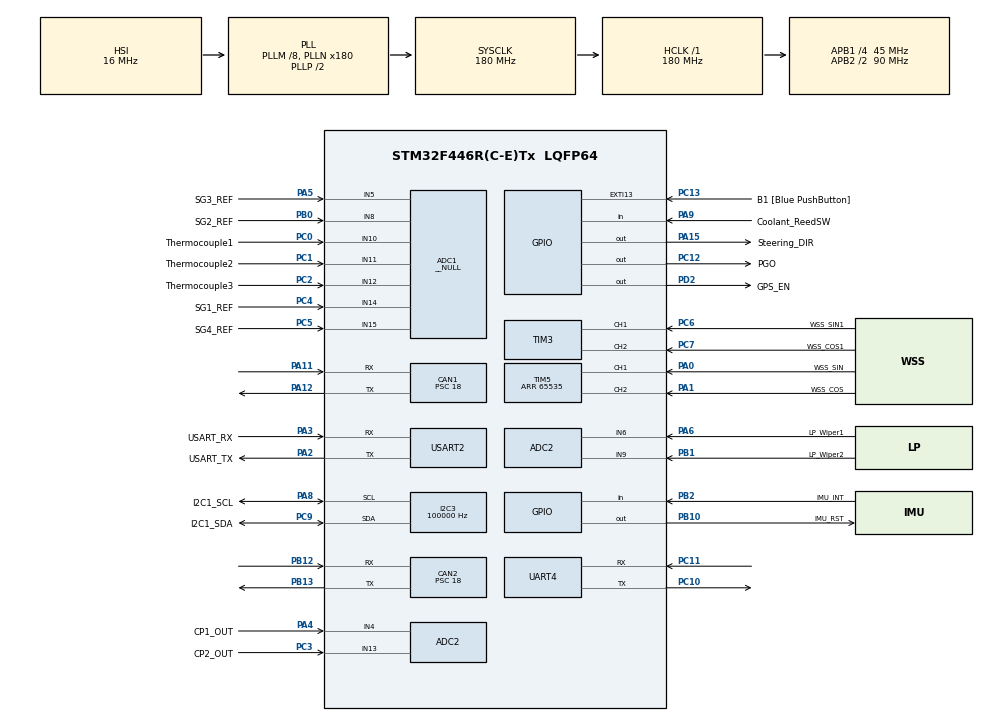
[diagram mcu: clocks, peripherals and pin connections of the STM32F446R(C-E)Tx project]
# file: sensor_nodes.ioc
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ADC1.Channel-0\#ChannelRegularConversion=ADC_CHANNEL_14
ADC1.Channel-1\#ChannelRegularConversion=ADC_CHANNEL_8
ADC1.Channel-2\#ChannelRegularConversion=ADC_CHANNEL_5
ADC1.Channel-3\#ChannelRegularConversion=ADC_CHANNEL_15
ADC1.Channel-4\#ChannelRegularConversion=ADC_CHANNEL_10
ADC1.Channel-5\#ChannelRegularConversion=ADC_CHANNEL_11
ADC1.Channel-6\#ChannelRegularConversion=ADC_CHANNEL_12
ADC1.ContinuousConvMode=DISABLE
ADC1.DMAContinuousRequests=DISABLE
ADC1.EOCSelection=ADC_EOC_SEQ_CONV
ADC1.Mode=__NULL
ADC1.NbrOfConversion=7
ADC1.NbrOfConversionFlag=1
ADC1.Rank-0\#ChannelRegularConversion=1
ADC1.Rank-1\#ChannelRegularConversion=2
ADC1.Rank-2\#ChannelRegularConversion=3
ADC1.Rank-3\#ChannelRegularConversion=4
ADC1.Rank-4\#ChannelRegularConversion=5
ADC1.Rank-5\#ChannelRegularConversion=6
ADC1.Rank-6\#ChannelRegularConversion=7
ADC1.SamplingTime-0\#ChannelRegularConversion=ADC_SAMPLETIME_3CYCLES
ADC1.SamplingTime-1\#ChannelRegularConversion=ADC_SAMPLETIME_3CYCLES
ADC1.SamplingTime-2\#ChannelRegularConversion=ADC_SAMPLETIME_3CYCLES
ADC1.SamplingTime-3\#ChannelRegularConversion=ADC_SAMPLETIME_3CYCLES
ADC1.SamplingTime-4\#ChannelRegularConversion=ADC_SAMPLETIME_3CYCLES
ADC1.SamplingTime-5\#ChannelRegularConversion=ADC_SAMPLETIME_3CYCLES
ADC1.SamplingTime-6\#ChannelRegularConversion=ADC_SAMPLETIME_3CYCLES
ADC1.master=1
ADC2.Channel-0\#ChannelRegularConversion=ADC_CHANNEL_6
ADC2.Channel-1\#ChannelRegularConversion=ADC_CHANNEL_9
ADC2.Channel-2\#ChannelRegularConversion=ADC_CHANNEL_4
ADC2.Channel-4\#ChannelRegularConversion=ADC_CHANNEL_13
ADC2.ContinuousConvMode=DISABLE
ADC2.DMAContinuousRequests=DISABLE
ADC2.DiscontinuousConvMode=DISABLE
ADC2.EOCSelection=ADC_EOC_SINGLE_CONV
ADC2.InjNumberOfConversion=0
ADC2.NbrOfConversion=4
ADC2.NbrOfConversionFlag=1
ADC2.Rank-0\#ChannelRegularConversion=1
ADC2.Rank-1\#ChannelRegularConversion=2
ADC2.Rank-2\#ChannelRegularConversion=3
ADC2.Rank-4\#ChannelRegularConversion=4
ADC2.SamplingTime-0\#ChannelRegularConversion=ADC_SAMPLETIME_112CYCLES
ADC2.SamplingTime-1\#ChannelRegularConversion=ADC_SAMPLETIME_112CYCLES
ADC2.SamplingTime-2\#ChannelRegularConversion=ADC_SAMPLETIME_112CYCLES
ADC2.SamplingTime-4\#ChannelRegularConversion=ADC_SAMPLETIME_112CYCLES
CAN1.BS1=CAN_BS1_3TQ
CAN1.BS2=CAN_BS2_1TQ
CAN1.CalculateBaudRate=500000
CAN1.CalculateTimeBit=2000
CAN1.CalculateTimeQuantum=400.0
CAN1.Prescaler=18
CAN2.BS1=CAN_BS1_3TQ
CAN2.BS2=CAN_BS2_1TQ
CAN2.CalculateBaudRate=500000
CAN2.CalculateTimeBit=2000
CAN2.CalculateTimeQuantum=400.0
CAN2.Prescaler=18
I2C3.ClockSpeed=100000
I2C3.DualAddressMode=I2C_DUALADDRESS_DISABLE
I2C3.I2C_Mode=I2C_Standard
I2C3.NoStretchMode=I2C_NOSTRETCH_DISABLE
I2C3.OwnAddress=0x4A
Mcu.Family=STM32F4
Mcu.Name=STM32F446R(C-E)Tx
Mcu.Package=LQFP64
NVIC.ADC_IRQn=true\:0\:0\:false\:false\:true\:true\:true\:true
NVIC.CAN1_RX0_IRQn=true\:0\:0\:false\:false\:true\:true\:true\:true
NVIC.CAN1_RX1_IRQn=true\:0\:0\:false\:false\:true\:true\:true\:true
NVIC.CAN2_RX0_IRQn=true\:0\:0\:false\:false\:true\:true\:true\:true
NVIC.CAN2_RX1_IRQn=true\:0\:0\:false\:false\:true\:true\:true\:true
NVIC.PriorityGroup=NVIC_PRIORITYGROUP_0
NVIC.TIM6_DAC_IRQn=true\:0\:0\:false\:false\:true\:true\:true\:true
PA0-WKUP.GPIO_Label=WSS_SIN
PA0-WKUP.Signal=S_TIM5_CH1
PA1.GPIO_Label=WSS_COS
PA1.Signal=S_TIM5_CH2
PA11.Mode=CAN_Activate
PA11.Signal=CAN1_RX
PA12.Mode=CAN_Activate
PA12.Signal=CAN1_TX
PA13.GPIO_Label=TMS
PA13.Mode=Serial_Wire
PA13.Signal=SYS_JTMS-SWDIO
PA14.GPIO_Label=TCK
PA14.Mode=Serial_Wire
PA14.Signal=SYS_JTCK-SWCLK
PA15.GPIO_Label=Steering_DIR
PA15.Signal=GPIO_Output
PA2.GPIO_Label=USART_TX
PA2.Mode=Asynchronous
PA2.Signal=USART2_TX
PA3.GPIO_Label=USART_RX
PA3.Mode=Asynchronous
PA3.Signal=USART2_RX
PA4.GPIO_Label=CP1_OUT
PA4.Signal=ADCx_IN4
PA5.GPIO_Label=SG3_REF
PA5.Signal=ADCx_IN5
PA6.GPIO_Label=LP_Wiper1
PA6.Signal=ADCx_IN6
PA8.GPIO_Label=I2C1_SCL
PA8.Mode=I2C
PA8.Signal=I2C3_SCL
PA9.GPIO_Label=Coolant_ReedSW
PA9.Signal=GPIO_Input
PB0.GPIO_Label=SG2_REF
PB0.Signal=ADCx_IN8
PB1.GPIO_Label=LP_Wiper2
PB1.Signal=ADCx_IN9
PB10.GPIO_Label=IMU_RST
PB10.Signal=GPIO_Output
PB12.Mode=CAN_Activate
PB12.Signal=CAN2_RX
PB13.Mode=CAN_Activate
PB13.Signal=CAN2_TX
PB2.GPIO_Label=IMU_INT
PB2.Signal=GPIO_Input
PC0.GPIO_Label=Thermocouple1
PC0.Signal=ADCx_IN10
PC1.GPIO_Label=Thermocouple2
PC1.Signal=ADCx_IN11
PC10.Mode=Asynchronous
PC10.Signal=UART4_TX
PC11.Mode=Asynchronous
PC11.Signal=UART4_RX
PC12.GPIO_Label=PGO
PC12.Signal=GPIO_Output
PC13.GPIO_Label=B1 [Blue PushButton]
PC13.GPIO_ModeDefaultEXTI=GPIO_MODE_IT_FALLING
PC13.Signal=GPXTI13
PC14-OSC32_IN.Mode=LSE-External-Oscillator
PC14-OSC32_IN.Signal=RCC_OSC32_IN
PC15-OSC32_OUT.Mode=LSE-External-Oscillator
PC15-OSC32_OUT.Signal=RCC_OSC32_OUT
PC2.GPIO_Label=Thermocouple3
PC2.Signal=ADCx_IN12
PC3.GPIO_Label=CP2_OUT
PC3.Signal=ADCx_IN13
PC4.GPIO_Label=SG1_REF
PC4.Signal=ADCx_IN14
PC5.GPIO_Label=SG4_REF
PC5.Signal=ADCx_IN15
PC6.GPIO_Label=WSS_SIN1
PC6.Signal=S_TIM3_CH1
PC7.GPIO_Label=WSS_COS1
PC7.Signal=S_TIM3_CH2
PC9.GPIO_Label=I2C1_SDA
PC9.Mode=I2C
PC9.Signal=I2C3_SDA
PD2.GPIO_Label=GPS_EN
PD2.Signal=GPIO_Output
PH0-OSC_IN.Mode=HSE-External-Oscillator
PH0-OSC_IN.Signal=RCC_OSC_IN
PH1-OSC_OUT.Mode=HSE-External-Oscillator
PH1-OSC_OUT.Signal=RCC_OSC_OUT
ProjectManager.HeapSize=0x200
ProjectManager.StackSize=0x400
ProjectManager.TargetToolchain=STM32CubeIDE
RCC.48MHZClocksFreq_Value=84000000
RCC.AHBFreq_Value=180000000
RCC.APB1CLKDivider=RCC_HCLK_DIV4
RCC.APB1Freq_Value=45000000
RCC.APB1TimFreq_Value=90000000
RCC.APB2CLKDivider=RCC_HCLK_DIV2
RCC.APB2Freq_Value=90000000
RCC.APB2TimFreq_Value=180000000
RCC.CortexFreq_Value=180000000
RCC.FLatency-AdvancedSettings=FLASH_LATENCY_5
RCC.HCLKFreq_Value=180000000
RCC.HSE_VALUE=8000000
RCC.HSI_VALUE=16000000
RCC.PLLM=8
RCC.PLLN=180
RCC.SYSCLKFreq_VALUE=180000000
RCC.SYSCLKSource=RCC_SYSCLKSOURCE_PLLCLK
RCC.USBFreq_Value=180000000
RCC.VCOOutputFreq_Value=360000000
SH.ADCx_IN10.0=ADC1_IN10,IN10
SH.ADCx_IN11.0=ADC1_IN11,IN11
SH.ADCx_IN12.0=ADC1_IN12,IN12
SH.ADCx_IN13.0=ADC2_IN13,IN13
SH.ADCx_IN14.0=ADC1_IN14,IN14
SH.ADCx_IN15.0=ADC1_IN15,IN15
SH.ADCx_IN4.0=ADC2_IN4,IN4
SH.ADCx_IN5.0=ADC1_IN5,IN5
SH.ADCx_IN6.0=ADC2_IN6,IN6
SH.ADCx_IN8.0=ADC1_IN8,IN8
SH.ADCx_IN9.0=ADC2_IN9,IN9
SH.S_TIM3_CH1.0=TIM3_CH1,Encoder_Interface
SH.S_TIM3_CH2.0=TIM3_CH2,Encoder_Interface
SH.S_TIM5_CH1.0=TIM5_CH1,Encoder_Interface
SH.S_TIM5_CH2.0=TIM5_CH2,Encoder_Interface
TIM3.AutoReloadPreload=TIM_AUTORELOAD_PRELOAD_ENABLE
TIM3.EncoderMode=TIM_ENCODERMODE_TI12
TIM5.AutoReloadPreload=TIM_AUTORELOAD_PRELOAD_ENABLE
TIM5.EncoderMode=TIM_ENCODERMODE_TI12
TIM5.Period=65535
TIM6.AutoReloadPreload=TIM_AUTORELOAD_PRELOAD_ENABLE
TIM6.Period=10000-1
TIM6.Prescaler=4500-1
UART4.VirtualMode=Asynchronous
USART2.VirtualMode=VM_ASYNC
VP_TIM6_VS_ClockSourceINT.Mode=Enable_Timer
board=NUCLEO-F446RE

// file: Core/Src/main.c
/* USER CODE BEGIN Header */
/**
  ******************************************************************************
  * @file           : main.c
  * @brief          : Main program body
  ******************************************************************************
  * @attention
  *
  * Copyright (c) 2024 STMicroelectronics.
  * All rights reserved.
  *
  * This software is licensed under terms that can be found in the LICENSE file
  * in the root directory of this software component.
  * If no LICENSE file comes with this software, it is provided AS-IS.
  *
  ******************************************************************************
  */
/* USER CODE END Header */
#include "main.h"

/* USER CODE BEGIN Includes */
#include "FEB_Main.h"
/* USER CODE END Includes */

ADC_HandleTypeDef hadc1;
ADC_HandleTypeDef hadc2;

CAN_HandleTypeDef hcan1;
CAN_HandleTypeDef hcan2;

I2C_HandleTypeDef hi2c3;

TIM_HandleTypeDef htim3;
TIM_HandleTypeDef htim5;
TIM_HandleTypeDef htim6;

UART_HandleTypeDef huart4;
UART_HandleTypeDef huart2;

void SystemClock_Config(void);
static void MX_GPIO_Init(void);
static void MX_USART2_UART_Init(void);
static void MX_I2C3_Init(void);
static void MX_TIM6_Init(void);
static void MX_CAN1_Init(void);
static void MX_CAN2_Init(void);
static void MX_ADC1_Init(void);
static void MX_ADC2_Init(void);
static void MX_TIM3_Init(void);
static void MX_TIM5_Init(void);
static void MX_UART4_Init(void);

/* USER CODE BEGIN 0 */
#ifdef __GNUC__
#define PUTCHAR_PROTOTYPE int __io_putchar(int ch)
#else
#define PUTCHAR_PROTOTYPE int fputc(int ch, FILE *f)
#endif
PUTCHAR_PROTOTYPE {
  HAL_UART_Transmit(&huart2, (uint8_t *)&ch, 1, HAL_MAX_DELAY);
  return ch;
}
/* USER CODE END 0 */

int main(void)
{

  /* MCU Configuration--------------------------------------------------------*/

  /* Reset of all peripherals, Initializes the Flash interface and the Systick. */
  HAL_Init();

  /* Configure the system clock */
  SystemClock_Config();

  /* Initialize all configured peripherals */
  MX_GPIO_Init();
  MX_USART2_UART_Init();
  MX_I2C3_Init();
  MX_TIM6_Init();
  MX_CAN1_Init();
  MX_CAN2_Init();
  MX_ADC1_Init();
  MX_ADC2_Init();
  MX_TIM3_Init();
  MX_TIM5_Init();
  MX_UART4_Init();
  /* USER CODE BEGIN 2 */
  FEB_Main_Setup();
  /* USER CODE END 2 */

  /* Infinite loop */
  /* USER CODE BEGIN WHILE */
  while (1)
  {
	  FEB_Main_While();
    /* USER CODE END WHILE */

  }
}

void SystemClock_Config(void)
{
  RCC_OscInitTypeDef RCC_OscInitStruct = {0};
  RCC_ClkInitTypeDef RCC_ClkInitStruct = {0};

  /** Configure the main internal regulator output voltage
  */
  __HAL_RCC_PWR_CLK_ENABLE();
  __HAL_PWR_VOLTAGESCALING_CONFIG(PWR_REGULATOR_VOLTAGE_SCALE1);

  /** Initializes the RCC Oscillators according to the specified parameters
  * in the RCC_OscInitTypeDef structure.
  */
  RCC_OscInitStruct.OscillatorType = RCC_OSCILLATORTYPE_HSI;
  RCC_OscInitStruct.HSIState = RCC_HSI_ON;
  RCC_OscInitStruct.HSICalibrationValue = RCC_HSICALIBRATION_DEFAULT;
  RCC_OscInitStruct.PLL.PLLState = RCC_PLL_ON;
  RCC_OscInitStruct.PLL.PLLSource = RCC_PLLSOURCE_HSI;
  RCC_OscInitStruct.PLL.PLLM = 8;
  RCC_OscInitStruct.PLL.PLLN = 180;
  RCC_OscInitStruct.PLL.PLLP = RCC_PLLP_DIV2;
  RCC_OscInitStruct.PLL.PLLQ = 2;
  RCC_OscInitStruct.PLL.PLLR = 2;
  if (HAL_RCC_OscConfig(&RCC_OscInitStruct) != HAL_OK)
  {
    Error_Handler();
  }

  /** Activate the Over-Drive mode
  */
  if (HAL_PWREx_EnableOverDrive() != HAL_OK)
  {
    Error_Handler();
  }

  /** Initializes the CPU, AHB and APB buses clocks
  */
  RCC_ClkInitStruct.ClockType = RCC_CLOCKTYPE_HCLK|RCC_CLOCKTYPE_SYSCLK
                              |RCC_CLOCKTYPE_PCLK1|RCC_CLOCKTYPE_PCLK2;
  RCC_ClkInitStruct.SYSCLKSource = RCC_SYSCLKSOURCE_PLLCLK;
  RCC_ClkInitStruct.AHBCLKDivider = RCC_SYSCLK_DIV1;
  RCC_ClkInitStruct.APB1CLKDivider = RCC_HCLK_DIV4;
  RCC_ClkInitStruct.APB2CLKDivider = RCC_HCLK_DIV2;

  if (HAL_RCC_ClockConfig(&RCC_ClkInitStruct, FLASH_LATENCY_5) != HAL_OK)
  {
    Error_Handler();
  }
}

static void MX_ADC1_Init(void)
{

  ADC_ChannelConfTypeDef sConfig = {0};

  /** Configure the global features of the ADC (Clock, Resolution, Data Alignment and number of conversion)
  */
  hadc1.Instance = ADC1;
  hadc1.Init.ClockPrescaler = ADC_CLOCK_SYNC_PCLK_DIV4;
  hadc1.Init.Resolution = ADC_RESOLUTION_12B;
  hadc1.Init.ScanConvMode = ENABLE;
  hadc1.Init.ContinuousConvMode = DISABLE;
  hadc1.Init.DiscontinuousConvMode = DISABLE;
  hadc1.Init.ExternalTrigConvEdge = ADC_EXTERNALTRIGCONVEDGE_NONE;
  hadc1.Init.ExternalTrigConv = ADC_SOFTWARE_START;
  hadc1.Init.DataAlign = ADC_DATAALIGN_RIGHT;
  hadc1.Init.NbrOfConversion = 7;
  hadc1.Init.DMAContinuousRequests = DISABLE;
  hadc1.Init.EOCSelection = ADC_EOC_SEQ_CONV;
  if (HAL_ADC_Init(&hadc1) != HAL_OK)
  {
    Error_Handler();
  }

  /** Configure for the selected ADC regular channel its corresponding rank in the sequencer and its sample time.
  */
  sConfig.Channel = ADC_CHANNEL_14;
  sConfig.Rank = 1;
  sConfig.SamplingTime = ADC_SAMPLETIME_3CYCLES;
  if (HAL_ADC_ConfigChannel(&hadc1, &sConfig) != HAL_OK)
  {
    Error_Handler();
  }

  /** Configure for the selected ADC regular channel its corresponding rank in the sequencer and its sample time.
  */
  sConfig.Channel = ADC_CHANNEL_8;
  sConfig.Rank = 2;
  if (HAL_ADC_ConfigChannel(&hadc1, &sConfig) != HAL_OK)
  {
    Error_Handler();
  }

  /** Configure for the selected ADC regular channel its corresponding rank in the sequencer and its sample time.
  */
  sConfig.Channel = ADC_CHANNEL_5;
  sConfig.Rank = 3;
  if (HAL_ADC_ConfigChannel(&hadc1, &sConfig) != HAL_OK)
  {
    Error_Handler();
  }

  /** Configure for the selected ADC regular channel its corresponding rank in the sequencer and its sample time.
  */
  sConfig.Channel = ADC_CHANNEL_15;
  sConfig.Rank = 4;
  if (HAL_ADC_ConfigChannel(&hadc1, &sConfig) != HAL_OK)
  {
    Error_Handler();
  }

  /** Configure for the selected ADC regular channel its corresponding rank in the sequencer and its sample time.
  */
  sConfig.Channel = ADC_CHANNEL_10;
  sConfig.Rank = 5;
  if (HAL_ADC_ConfigChannel(&hadc1, &sConfig) != HAL_OK)
  {
    Error_Handler();
  }

  /** Configure for the selected ADC regular channel its corresponding rank in the sequencer and its sample time.
  */
  sConfig.Channel = ADC_CHANNEL_11;
  sConfig.Rank = 6;
  if (HAL_ADC_ConfigChannel(&hadc1, &sConfig) != HAL_OK)
  {
    Error_Handler();
  }

  /** Configure for the selected ADC regular channel its corresponding rank in the sequencer and its sample time.
  */
  sConfig.Channel = ADC_CHANNEL_12;
  sConfig.Rank = 7;
  if (HAL_ADC_ConfigChannel(&hadc1, &sConfig) != HAL_OK)
  {
    Error_Handler();
  }

}

static void MX_ADC2_Init(void)
{

  ADC_ChannelConfTypeDef sConfig = {0};

  /** Configure the global features of the ADC (Clock, Resolution, Data Alignment and number of conversion)
  */
  hadc2.Instance = ADC2;
  hadc2.Init.ClockPrescaler = ADC_CLOCK_SYNC_PCLK_DIV4;
  hadc2.Init.Resolution = ADC_RESOLUTION_12B;
  hadc2.Init.ScanConvMode = ENABLE;
  hadc2.Init.ContinuousConvMode = DISABLE;
  hadc2.Init.DiscontinuousConvMode = DISABLE;
  hadc2.Init.ExternalTrigConvEdge = ADC_EXTERNALTRIGCONVEDGE_NONE;
  hadc2.Init.ExternalTrigConv = ADC_SOFTWARE_START;
  hadc2.Init.DataAlign = ADC_DATAALIGN_RIGHT;
  hadc2.Init.NbrOfConversion = 4;
  hadc2.Init.DMAContinuousRequests = DISABLE;
  hadc2.Init.EOCSelection = ADC_EOC_SINGLE_CONV;
  if (HAL_ADC_Init(&hadc2) != HAL_OK)
  {
    Error_Handler();
  }

  /** Configure for the selected ADC regular channel its corresponding rank in the sequencer and its sample time.
  */
  sConfig.Channel = ADC_CHANNEL_6;
  sConfig.Rank = 1;
  sConfig.SamplingTime = ADC_SAMPLETIME_112CYCLES;
  if (HAL_ADC_ConfigChannel(&hadc2, &sConfig) != HAL_OK)
  {
    Error_Handler();
  }

  /** Configure for the selected ADC regular channel its corresponding rank in the sequencer and its sample time.
  */
  sConfig.Channel = ADC_CHANNEL_9;
  sConfig.Rank = 2;
  if (HAL_ADC_ConfigChannel(&hadc2, &sConfig) != HAL_OK)
  {
    Error_Handler();
  }

  /** Configure for the selected ADC regular channel its corresponding rank in the sequencer and its sample time.
  */
  sConfig.Channel = ADC_CHANNEL_4;
  sConfig.Rank = 3;
  if (HAL_ADC_ConfigChannel(&hadc2, &sConfig) != HAL_OK)
  {
    Error_Handler();
  }

  /** Configure for the selected ADC regular channel its corresponding rank in the sequencer and its sample time.
  */
  sConfig.Channel = ADC_CHANNEL_13;
  sConfig.Rank = 4;
  if (HAL_ADC_ConfigChannel(&hadc2, &sConfig) != HAL_OK)
  {
    Error_Handler();
  }

}

static void MX_CAN1_Init(void)
{

  hcan1.Instance = CAN1;
  hcan1.Init.Prescaler = 18;
  hcan1.Init.Mode = CAN_MODE_NORMAL;
  hcan1.Init.SyncJumpWidth = CAN_SJW_1TQ;
  hcan1.Init.TimeSeg1 = CAN_BS1_3TQ;
  hcan1.Init.TimeSeg2 = CAN_BS2_1TQ;
  hcan1.Init.TimeTriggeredMode = DISABLE;
  hcan1.Init.AutoBusOff = DISABLE;
  hcan1.Init.AutoWakeUp = DISABLE;
  hcan1.Init.AutoRetransmission = DISABLE;
  hcan1.Init.ReceiveFifoLocked = DISABLE;
  hcan1.Init.TransmitFifoPriority = DISABLE;
  if (HAL_CAN_Init(&hcan1) != HAL_OK)
  {
    Error_Handler();
  }

}

static void MX_CAN2_Init(void)
{

  hcan2.Instance = CAN2;
  hcan2.Init.Prescaler = 18;
  hcan2.Init.Mode = CAN_MODE_NORMAL;
  hcan2.Init.SyncJumpWidth = CAN_SJW_1TQ;
  hcan2.Init.TimeSeg1 = CAN_BS1_3TQ;
  hcan2.Init.TimeSeg2 = CAN_BS2_1TQ;
  hcan2.Init.TimeTriggeredMode = DISABLE;
  hcan2.Init.AutoBusOff = DISABLE;
  hcan2.Init.AutoWakeUp = DISABLE;
  hcan2.Init.AutoRetransmission = DISABLE;
  hcan2.Init.ReceiveFifoLocked = DISABLE;
  hcan2.Init.TransmitFifoPriority = DISABLE;
  if (HAL_CAN_Init(&hcan2) != HAL_OK)
  {
    Error_Handler();
  }

}

static void MX_I2C3_Init(void)
{

  hi2c3.Instance = I2C3;
  hi2c3.Init.ClockSpeed = 100000;
  hi2c3.Init.DutyCycle = I2C_DUTYCYCLE_2;
  hi2c3.Init.OwnAddress1 = 148;
  hi2c3.Init.AddressingMode = I2C_ADDRESSINGMODE_7BIT;
  hi2c3.Init.DualAddressMode = I2C_DUALADDRESS_DISABLE;
  hi2c3.Init.OwnAddress2 = 0;
  hi2c3.Init.GeneralCallMode = I2C_GENERALCALL_DISABLE;
  hi2c3.Init.NoStretchMode = I2C_NOSTRETCH_DISABLE;
  if (HAL_I2C_Init(&hi2c3) != HAL_OK)
  {
    Error_Handler();
  }

}

static void MX_TIM3_Init(void)
{

  TIM_Encoder_InitTypeDef sConfig = {0};
  TIM_MasterConfigTypeDef sMasterConfig = {0};

  htim3.Instance = TIM3;
  htim3.Init.Prescaler = 0;
  htim3.Init.CounterMode = TIM_COUNTERMODE_UP;
  htim3.Init.Period = 65535;
  htim3.Init.ClockDivision = TIM_CLOCKDIVISION_DIV1;
  htim3.Init.AutoReloadPreload = TIM_AUTORELOAD_PRELOAD_ENABLE;
  sConfig.EncoderMode = TIM_ENCODERMODE_TI12;
  sConfig.IC1Polarity = TIM_ICPOLARITY_RISING;
  sConfig.IC1Selection = TIM_ICSELECTION_DIRECTTI;
  sConfig.IC1Prescaler = TIM_ICPSC_DIV1;
  sConfig.IC1Filter = 0;
  sConfig.IC2Polarity = TIM_ICPOLARITY_RISING;
  sConfig.IC2Selection = TIM_ICSELECTION_DIRECTTI;
  sConfig.IC2Prescaler = TIM_ICPSC_DIV1;
  sConfig.IC2Filter = 0;
  if (HAL_TIM_Encoder_Init(&htim3, &sConfig) != HAL_OK)
  {
    Error_Handler();
  }
  sMasterConfig.MasterOutputTrigger = TIM_TRGO_RESET;
  sMasterConfig.MasterSlaveMode = TIM_MASTERSLAVEMODE_DISABLE;
  if (HAL_TIMEx_MasterConfigSynchronization(&htim3, &sMasterConfig) != HAL_OK)
  {
    Error_Handler();
  }

}

static void MX_TIM5_Init(void)
{

  TIM_Encoder_InitTypeDef sConfig = {0};
  TIM_MasterConfigTypeDef sMasterConfig = {0};

  htim5.Instance = TIM5;
  htim5.Init.Prescaler = 0;
  htim5.Init.CounterMode = TIM_COUNTERMODE_UP;
  htim5.Init.Period = 65535;
  htim5.Init.ClockDivision = TIM_CLOCKDIVISION_DIV1;
  htim5.Init.AutoReloadPreload = TIM_AUTORELOAD_PRELOAD_ENABLE;
  sConfig.EncoderMode = TIM_ENCODERMODE_TI12;
  sConfig.IC1Polarity = TIM_ICPOLARITY_RISING;
  sConfig.IC1Selection = TIM_ICSELECTION_DIRECTTI;
  sConfig.IC1Prescaler = TIM_ICPSC_DIV1;
  sConfig.IC1Filter = 0;
  sConfig.IC2Polarity = TIM_ICPOLARITY_RISING;
  sConfig.IC2Selection = TIM_ICSELECTION_DIRECTTI;
  sConfig.IC2Prescaler = TIM_ICPSC_DIV1;
  sConfig.IC2Filter = 0;
  if (HAL_TIM_Encoder_Init(&htim5, &sConfig) != HAL_OK)
  {
    Error_Handler();
  }
  sMasterConfig.MasterOutputTrigger = TIM_TRGO_RESET;
  sMasterConfig.MasterSlaveMode = TIM_MASTERSLAVEMODE_DISABLE;
  if (HAL_TIMEx_MasterConfigSynchronization(&htim5, &sMasterConfig) != HAL_OK)
  {
    Error_Handler();
  }

}

static void MX_TIM6_Init(void)
{

  TIM_MasterConfigTypeDef sMasterConfig = {0};

  htim6.Instance = TIM6;
  htim6.Init.Prescaler = 4500-1;
  htim6.Init.CounterMode = TIM_COUNTERMODE_UP;
  htim6.Init.Period = 10000-1;
  htim6.Init.AutoReloadPreload = TIM_AUTORELOAD_PRELOAD_ENABLE;
  if (HAL_TIM_Base_Init(&htim6) != HAL_OK)
  {
    Error_Handler();
  }
  sMasterConfig.MasterOutputTrigger = TIM_TRGO_RESET;
  sMasterConfig.MasterSlaveMode = TIM_MASTERSLAVEMODE_DISABLE;
  if (HAL_TIMEx_MasterConfigSynchronization(&htim6, &sMasterConfig) != HAL_OK)
  {
    Error_Handler();
  }

}

static void MX_UART4_Init(void)
{

  huart4.Instance = UART4;
  huart4.Init.BaudRate = 115200;
  huart4.Init.WordLength = UART_WORDLENGTH_8B;
  huart4.Init.StopBits = UART_STOPBITS_1;
  huart4.Init.Parity = UART_PARITY_NONE;
  huart4.Init.Mode = UART_MODE_TX_RX;
  huart4.Init.HwFlowCtl = UART_HWCONTROL_NONE;
  huart4.Init.OverSampling = UART_OVERSAMPLING_16;
  if (HAL_UART_Init(&huart4) != HAL_OK)
  {
    Error_Handler();
  }

}

static void MX_USART2_UART_Init(void)
{

  huart2.Instance = USART2;
  huart2.Init.BaudRate = 115200;
  huart2.Init.WordLength = UART_WORDLENGTH_8B;
  huart2.Init.StopBits = UART_STOPBITS_1;
  huart2.Init.Parity = UART_PARITY_NONE;
  huart2.Init.Mode = UART_MODE_TX_RX;
  huart2.Init.HwFlowCtl = UART_HWCONTROL_NONE;
  huart2.Init.OverSampling = UART_OVERSAMPLING_16;
  if (HAL_UART_Init(&huart2) != HAL_OK)
  {
    Error_Handler();
  }

}

static void MX_GPIO_Init(void)
{
  GPIO_InitTypeDef GPIO_InitStruct = {0};

  /* GPIO Ports Clock Enable */
  __HAL_RCC_GPIOC_CLK_ENABLE();
  __HAL_RCC_GPIOH_CLK_ENABLE();
  __HAL_RCC_GPIOA_CLK_ENABLE();
  __HAL_RCC_GPIOB_CLK_ENABLE();
  __HAL_RCC_GPIOD_CLK_ENABLE();

  /*Configure GPIO pin Output Level */
  HAL_GPIO_WritePin(IMU_RST_GPIO_Port, IMU_RST_Pin, GPIO_PIN_RESET);

  /*Configure GPIO pin Output Level */
  HAL_GPIO_WritePin(Steering_DIR_GPIO_Port, Steering_DIR_Pin, GPIO_PIN_RESET);

  /*Configure GPIO pin Output Level */
  HAL_GPIO_WritePin(PGO_GPIO_Port, PGO_Pin, GPIO_PIN_RESET);

  /*Configure GPIO pin Output Level */
  HAL_GPIO_WritePin(GPS_EN_GPIO_Port, GPS_EN_Pin, GPIO_PIN_RESET);

  /*Configure GPIO pin : B1_Pin */
  GPIO_InitStruct.Pin = B1_Pin;
  GPIO_InitStruct.Mode = GPIO_MODE_IT_FALLING;
  GPIO_InitStruct.Pull = GPIO_NOPULL;
  HAL_GPIO_Init(B1_GPIO_Port, &GPIO_InitStruct);

  /*Configure GPIO pin : IMU_INT_Pin */
  GPIO_InitStruct.Pin = IMU_INT_Pin;
  GPIO_InitStruct.Mode = GPIO_MODE_INPUT;
  GPIO_InitStruct.Pull = GPIO_NOPULL;
  HAL_GPIO_Init(IMU_INT_GPIO_Port, &GPIO_InitStruct);

  /*Configure GPIO pin : IMU_RST_Pin */
  GPIO_InitStruct.Pin = IMU_RST_Pin;
  GPIO_InitStruct.Mode = GPIO_MODE_OUTPUT_PP;
  GPIO_InitStruct.Pull = GPIO_NOPULL;
  GPIO_InitStruct.Speed = GPIO_SPEED_FREQ_LOW;
  HAL_GPIO_Init(IMU_RST_GPIO_Port, &GPIO_InitStruct);

  /*Configure GPIO pin : Coolant_ReedSW_Pin */
  GPIO_InitStruct.Pin = Coolant_ReedSW_Pin;
  GPIO_InitStruct.Mode = GPIO_MODE_INPUT;
  GPIO_InitStruct.Pull = GPIO_NOPULL;
  HAL_GPIO_Init(Coolant_ReedSW_GPIO_Port, &GPIO_InitStruct);

  /*Configure GPIO pin : Steering_DIR_Pin */
  GPIO_InitStruct.Pin = Steering_DIR_Pin;
  GPIO_InitStruct.Mode = GPIO_MODE_OUTPUT_PP;
  GPIO_InitStruct.Pull = GPIO_NOPULL;
  GPIO_InitStruct.Speed = GPIO_SPEED_FREQ_LOW;
  HAL_GPIO_Init(Steering_DIR_GPIO_Port, &GPIO_InitStruct);

  /*Configure GPIO pin : PGO_Pin */
  GPIO_InitStruct.Pin = PGO_Pin;
  GPIO_InitStruct.Mode = GPIO_MODE_OUTPUT_PP;
  GPIO_InitStruct.Pull = GPIO_NOPULL;
  GPIO_InitStruct.Speed = GPIO_SPEED_FREQ_LOW;
  HAL_GPIO_Init(PGO_GPIO_Port, &GPIO_InitStruct);

  /*Configure GPIO pin : GPS_EN_Pin */
  GPIO_InitStruct.Pin = GPS_EN_Pin;
  GPIO_InitStruct.Mode = GPIO_MODE_OUTPUT_PP;
  GPIO_InitStruct.Pull = GPIO_NOPULL;
  GPIO_InitStruct.Speed = GPIO_SPEED_FREQ_LOW;
  HAL_GPIO_Init(GPS_EN_GPIO_Port, &GPIO_InitStruct);

}

void Error_Handler(void)
{
  __disable_irq();
  while (1)
  {
  }
}
